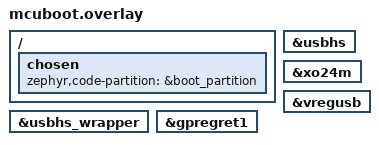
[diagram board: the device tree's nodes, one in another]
#include "layout.dtsi"
/ { chosen { zephyr,code-partition = &boot_partition; }; };
&usbhs_wrapper { status = "okay"; };
zephyr_udc0: &usbhs { status = "okay"; };
&xo24m { status = "okay"; };
&vregusb { status = "okay"; };
&gpregret1 { status = "okay"; };
